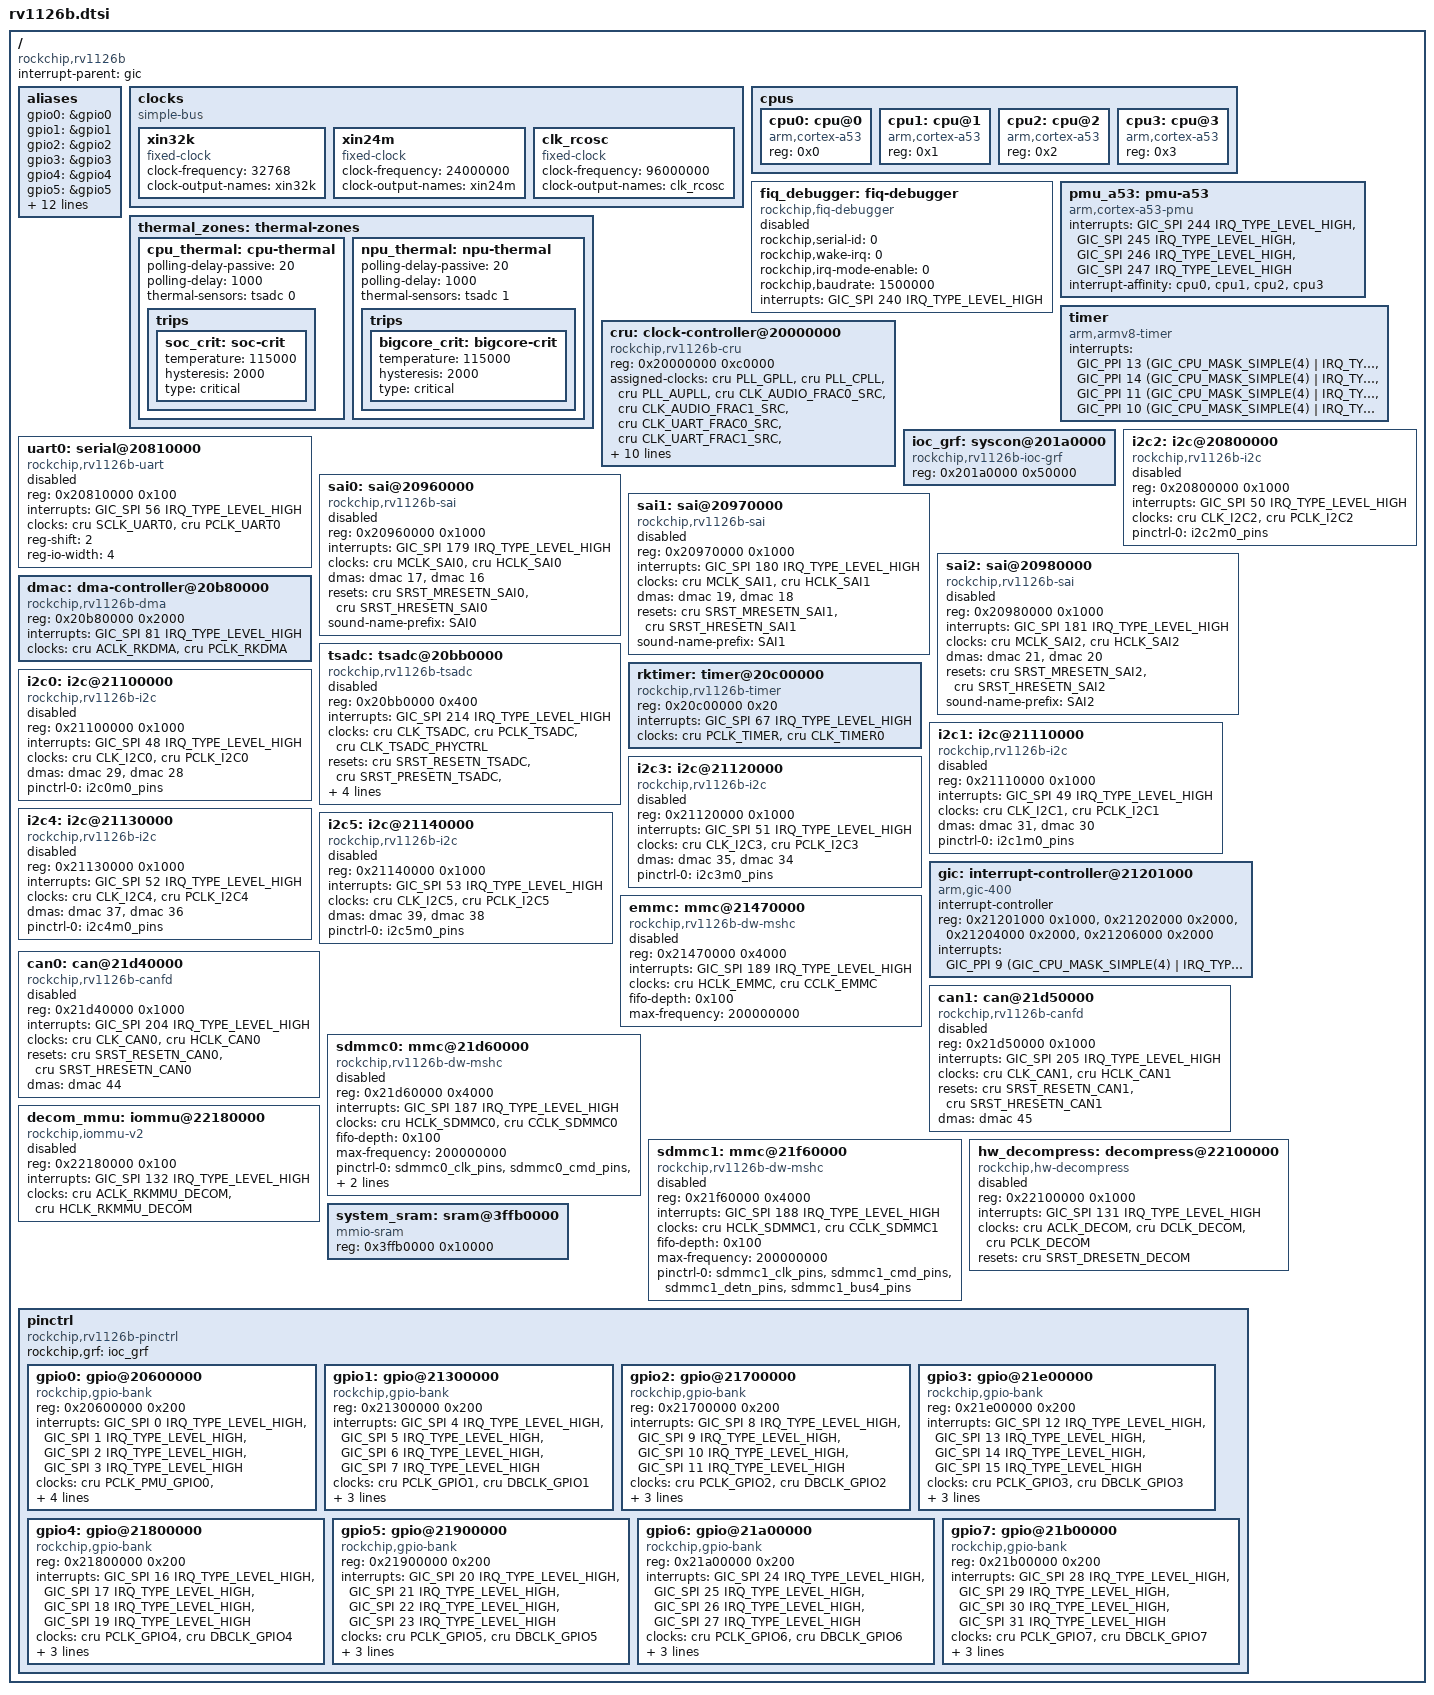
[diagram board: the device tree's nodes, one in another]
// SPDX-License-Identifier: (GPL-2.0+ OR MIT)
/*
 * Copyright (c) 2024 Rockchip Electronics Co., Ltd.
 */

#include <dt-bindings/clock/rockchip,rv1126b-cru.h>
#include <dt-bindings/interrupt-controller/arm-gic.h>
#include <dt-bindings/interrupt-controller/irq.h>
#include <dt-bindings/pinctrl/rockchip.h>
#include <dt-bindings/soc/rockchip,boot-mode.h>
#include <dt-bindings/soc/rockchip-system-status.h>

/ {
	compatible = "rockchip,rv1126b";

	interrupt-parent = <&gic>;
	#address-cells = <1>;
	#size-cells = <1>;

	aliases {
		gpio0 = &gpio0;
		gpio1 = &gpio1;
		gpio2 = &gpio2;
		gpio3 = &gpio3;
		gpio4 = &gpio4;
		gpio5 = &gpio5;
		gpio6 = &gpio6;
		gpio7 = &gpio7;
		i2c0 = &i2c0;
		i2c1 = &i2c1;
		i2c2 = &i2c2;
		i2c3 = &i2c3;
		i2c4 = &i2c4;
		i2c5 = &i2c5;
		mmc0 = &emmc;
		mmc1 = &sdmmc0;
		mmc2 = &sdmmc1;
		serial0 = &uart0;
	};

	clocks {
		compatible = "simple-bus";
		#address-cells = <1>;
		#size-cells = <1>;
		ranges;

		xin32k: xin32k {
			compatible = "fixed-clock";
			#clock-cells = <0>;
			clock-frequency = <32768>;
			clock-output-names = "xin32k";
		};

		xin24m: xin24m {
			compatible = "fixed-clock";
			#clock-cells = <0>;
			clock-frequency = <24000000>;
			clock-output-names = "xin24m";
		};

		clk_rcosc: clk_rcosc {
			compatible = "fixed-clock";
			#clock-cells = <0>;
			clock-frequency = <96000000>;
			clock-output-names = "clk_rcosc";
		};
	};

	cpus {
		#address-cells = <1>;
		#size-cells = <0>;

		cpu0: cpu@0 {
			device_type = "cpu";
			compatible = "arm,cortex-a53";
			reg = <0x0>;
		};
		cpu1: cpu@1 {
			device_type = "cpu";
			compatible = "arm,cortex-a53";
			reg = <0x1>;
		};
		cpu2: cpu@2 {
			device_type = "cpu";
			compatible = "arm,cortex-a53";
			reg = <0x2>;
		};
		cpu3: cpu@3 {
			device_type = "cpu";
			compatible = "arm,cortex-a53";
			reg = <0x3>;
		};
	};

	fiq_debugger: fiq-debugger {
		compatible = "rockchip,fiq-debugger";
		rockchip,serial-id = <0>;
		rockchip,wake-irq = <0>;
		rockchip,irq-mode-enable = <0>;
		rockchip,baudrate = <1500000>;  /* Only 115200 and 1500000 */
		interrupts = <GIC_SPI 240 IRQ_TYPE_LEVEL_HIGH>;
		status = "disabled";
	};

	pmu_a53: pmu-a53 {
		compatible = "arm,cortex-a53-pmu";
		interrupts = <GIC_SPI 244 IRQ_TYPE_LEVEL_HIGH>,
			     <GIC_SPI 245 IRQ_TYPE_LEVEL_HIGH>,
			     <GIC_SPI 246 IRQ_TYPE_LEVEL_HIGH>,
			     <GIC_SPI 247 IRQ_TYPE_LEVEL_HIGH>;
		interrupt-affinity = <&cpu0>, <&cpu1>, <&cpu2>, <&cpu3>;
	};

	thermal_zones: thermal-zones {
		cpu_thermal: cpu-thermal {
			polling-delay-passive = <20>; /* milliseconds */
			polling-delay = <1000>; /* milliseconds */
			thermal-sensors = <&tsadc 0>;
			trips {
				soc_crit: soc-crit {
					/* millicelsius */
					temperature = <115000>;
					/* millicelsius */
					hysteresis = <2000>;
					type = "critical";
				};
			};
		};
		npu_thermal: npu-thermal {
			polling-delay-passive = <20>; /* milliseconds */
			polling-delay = <1000>; /* milliseconds */
			thermal-sensors = <&tsadc 1>;
			trips {
				bigcore_crit: bigcore-crit {
					/* millicelsius */
					temperature = <115000>;
					/* millicelsius */
					hysteresis = <2000>;
					type = "critical";
				};
			};
		};
	};

	timer {
		compatible = "arm,armv8-timer";
		interrupts = <GIC_PPI 13 (GIC_CPU_MASK_SIMPLE(4) | IRQ_TYPE_LEVEL_LOW)>,
			     <GIC_PPI 14 (GIC_CPU_MASK_SIMPLE(4) | IRQ_TYPE_LEVEL_LOW)>,
			     <GIC_PPI 11 (GIC_CPU_MASK_SIMPLE(4) | IRQ_TYPE_LEVEL_LOW)>,
			     <GIC_PPI 10 (GIC_CPU_MASK_SIMPLE(4) | IRQ_TYPE_LEVEL_LOW)>;
	};

	cru: clock-controller@20000000 {
		compatible = "rockchip,rv1126b-cru";
		reg = <0x20000000 0xc0000>;
		#clock-cells = <1>;
		#reset-cells = <1>;

		assigned-clocks =
			<&cru PLL_GPLL>, <&cru PLL_CPLL>,
			<&cru PLL_AUPLL>, <&cru CLK_AUDIO_FRAC0_SRC>,
			<&cru CLK_AUDIO_FRAC1_SRC>, <&cru CLK_UART_FRAC0_SRC>,
			<&cru CLK_UART_FRAC1_SRC>, <&cru CLK_CM_FRAC0_SRC>,
			<&cru CLK_CM_FRAC1_SRC>, <&cru CLK_CM_FRAC2_SRC>,
			<&cru CLK_UART_FRAC0>, <&cru CLK_UART_FRAC1>,
			<&cru CLK_CM_FRAC0>, <&cru CLK_CM_FRAC1>,
			<&cru CLK_CM_FRAC2>, <&cru CLK_AUDIO_FRAC0>,
			<&cru CLK_AUDIO_FRAC1>;
		assigned-clock-rates =
			<1188000000>, <1000000000>,
			<786432000>, <786432000>,
			<786432000>, <1188000000>,
			<1188000000>, <1188000000>,
			<1188000000>, <786432000>,
			<96000000>, <128000000>,
			<18432000>, <500000000>,
			<250000000>, <45158400>,
			<49152000>;
	};

	ioc_grf: syscon@201a0000 {
		compatible = "rockchip,rv1126b-ioc-grf", "syscon";
		reg = <0x201a0000 0x50000>;
	};

	i2c2: i2c@20800000 {
		compatible = "rockchip,rv1126b-i2c", "rockchip,rk3399-i2c";
		reg = <0x20800000 0x1000>;
		interrupts = <GIC_SPI 50 IRQ_TYPE_LEVEL_HIGH>;
		#address-cells = <1>;
		#size-cells = <0>;
		clocks = <&cru CLK_I2C2>, <&cru PCLK_I2C2>;
		clock-names = "i2c", "pclk";
		pinctrl-names = "default";
		pinctrl-0 = <&i2c2m0_pins>;
		status = "disabled";
	};

	uart0: serial@20810000 {
		compatible = "rockchip,rv1126b-uart", "snps,dw-apb-uart";
		reg = <0x20810000 0x100>;
		interrupts = <GIC_SPI 56 IRQ_TYPE_LEVEL_HIGH>;
		clocks = <&cru SCLK_UART0>, <&cru PCLK_UART0>;
		clock-names = "baudclk", "apb_pclk";
		reg-shift = <2>;
		reg-io-width = <4>;
		status = "disabled";
	};

	sai0: sai@20960000 {
		compatible = "rockchip,rv1126b-sai", "rockchip,sai-v1";
		reg = <0x20960000 0x1000>;
		interrupts = <GIC_SPI 179 IRQ_TYPE_LEVEL_HIGH>;
		clocks = <&cru MCLK_SAI0>, <&cru HCLK_SAI0>;
		clock-names = "mclk", "hclk";
		dmas = <&dmac 17>, <&dmac 16>;
		dma-names = "tx", "rx";
		resets = <&cru SRST_MRESETN_SAI0>, <&cru SRST_HRESETN_SAI0>;
		reset-names = "m", "h";
		#sound-dai-cells = <0>;
		sound-name-prefix = "SAI0";
		status = "disabled";
	};

	sai1: sai@20970000 {
		compatible = "rockchip,rv1126b-sai", "rockchip,sai-v1";
		reg = <0x20970000 0x1000>;
		interrupts = <GIC_SPI 180 IRQ_TYPE_LEVEL_HIGH>;
		clocks = <&cru MCLK_SAI1>, <&cru HCLK_SAI1>;
		clock-names = "mclk", "hclk";
		dmas = <&dmac 19>, <&dmac 18>;
		dma-names = "tx", "rx";
		resets = <&cru SRST_MRESETN_SAI1>, <&cru SRST_HRESETN_SAI1>;
		reset-names = "m", "h";
		#sound-dai-cells = <0>;
		sound-name-prefix = "SAI1";
		status = "disabled";
	};

	sai2: sai@20980000 {
		compatible = "rockchip,rv1126b-sai", "rockchip,sai-v1";
		reg = <0x20980000 0x1000>;
		interrupts = <GIC_SPI 181 IRQ_TYPE_LEVEL_HIGH>;
		clocks = <&cru MCLK_SAI2>, <&cru HCLK_SAI2>;
		clock-names = "mclk", "hclk";
		dmas = <&dmac 21>, <&dmac 20>;
		dma-names = "tx", "rx";
		resets = <&cru SRST_MRESETN_SAI2>, <&cru SRST_HRESETN_SAI2>;
		reset-names = "m", "h";
		#sound-dai-cells = <0>;
		sound-name-prefix = "SAI2";
		status = "disabled";
	};

	dmac: dma-controller@20b80000 {
		compatible = "rockchip,rv1126b-dma", "rockchip,dma";
		reg = <0x20b80000 0x2000>;
		interrupts = <GIC_SPI 81 IRQ_TYPE_LEVEL_HIGH>;
		clocks = <&cru ACLK_RKDMA>, <&cru PCLK_RKDMA>;
		clock-names = "aclk", "pclk";
		#dma-cells = <1>;
	};

	tsadc: tsadc@20bb0000 {
		compatible = "rockchip,rv1126b-tsadc";
		reg = <0x20bb0000 0x400>;
		interrupts = <GIC_SPI 214 IRQ_TYPE_LEVEL_HIGH>;
		clocks = <&cru CLK_TSADC>, <&cru PCLK_TSADC>,
			 <&cru CLK_TSADC_PHYCTRL>;
		clock-names = "tsadc", "apb_pclk", "tsadc_phyctrl";
		resets = <&cru SRST_RESETN_TSADC>, <&cru SRST_PRESETN_TSADC>,
			 <&cru SRST_RESETN_TSADC_PHYCTRL>;
		reset-names = "tsadc", "tsadc-apb", "tsadc-phy";
		#thermal-sensor-cells = <1>;
		rockchip,hw-tshut-temp = <120000>;
		rockchip,hw-tshut-mode = <0>; /* tshut mode 0:CRU 1:GPIO */
		rockchip,hw-tshut-polarity = <0>; /* tshut polarity 0:LOW 1:HIGH */
		status = "disabled";
	};

	rktimer: timer@20c00000 {
		compatible = "rockchip,rv1126b-timer", "rockchip,rk3288-timer";
		reg = <0x20c00000 0x20>;
		interrupts = <GIC_SPI 67 IRQ_TYPE_LEVEL_HIGH>;
		clocks = <&cru PCLK_TIMER>, <&cru CLK_TIMER0>;
		clock-names = "pclk", "timer";
	};

	i2c0: i2c@21100000 {
		compatible = "rockchip,rv1126b-i2c", "rockchip,rk3399-i2c";
		reg = <0x21100000 0x1000>;
		interrupts = <GIC_SPI 48 IRQ_TYPE_LEVEL_HIGH>;
		#address-cells = <1>;
		#size-cells = <0>;
		clocks = <&cru CLK_I2C0>, <&cru PCLK_I2C0>;
		clock-names = "i2c", "pclk";
		dmas = <&dmac 29>, <&dmac 28>;
		dma-names = "tx", "rx";
		pinctrl-names = "default";
		pinctrl-0 = <&i2c0m0_pins>;
		status = "disabled";
	};

	i2c1: i2c@21110000 {
		compatible = "rockchip,rv1126b-i2c", "rockchip,rk3399-i2c";
		reg = <0x21110000 0x1000>;
		interrupts = <GIC_SPI 49 IRQ_TYPE_LEVEL_HIGH>;
		#address-cells = <1>;
		#size-cells = <0>;
		clocks = <&cru CLK_I2C1>, <&cru PCLK_I2C1>;
		clock-names = "i2c", "pclk";
		dmas = <&dmac 31>, <&dmac 30>;
		dma-names = "tx", "rx";
		pinctrl-names = "default";
		pinctrl-0 = <&i2c1m0_pins>;
		status = "disabled";
	};

	i2c3: i2c@21120000 {
		compatible = "rockchip,rv1126b-i2c", "rockchip,rk3399-i2c";
		reg = <0x21120000 0x1000>;
		interrupts = <GIC_SPI 51 IRQ_TYPE_LEVEL_HIGH>;
		#address-cells = <1>;
		#size-cells = <0>;
		clocks = <&cru CLK_I2C3>, <&cru PCLK_I2C3>;
		clock-names = "i2c", "pclk";
		dmas = <&dmac 35>, <&dmac 34>;
		dma-names = "tx", "rx";
		pinctrl-names = "default";
		pinctrl-0 = <&i2c3m0_pins>;
		status = "disabled";
	};

	i2c4: i2c@21130000 {
		compatible = "rockchip,rv1126b-i2c", "rockchip,rk3399-i2c";
		reg = <0x21130000 0x1000>;
		interrupts = <GIC_SPI 52 IRQ_TYPE_LEVEL_HIGH>;
		#address-cells = <1>;
		#size-cells = <0>;
		clocks = <&cru CLK_I2C4>, <&cru PCLK_I2C4>;
		clock-names = "i2c", "pclk";
		dmas = <&dmac 37>, <&dmac 36>;
		dma-names = "tx", "rx";
		pinctrl-names = "default";
		pinctrl-0 = <&i2c4m0_pins>;
		status = "disabled";
	};

	i2c5: i2c@21140000 {
		compatible = "rockchip,rv1126b-i2c", "rockchip,rk3399-i2c";
		reg = <0x21140000 0x1000>;
		interrupts = <GIC_SPI 53 IRQ_TYPE_LEVEL_HIGH>;
		#address-cells = <1>;
		#size-cells = <0>;
		clocks = <&cru CLK_I2C5>, <&cru PCLK_I2C5>;
		clock-names = "i2c", "pclk";
		dmas = <&dmac 39>, <&dmac 38>;
		dma-names = "tx", "rx";
		pinctrl-names = "default";
		pinctrl-0 = <&i2c5m0_pins>;
		status = "disabled";
	};

	gic: interrupt-controller@21201000 {
		compatible = "arm,gic-400";
		#interrupt-cells = <3>;
		#address-cells = <0>;
		interrupt-controller;
		reg = <0x21201000 0x1000>,
		      <0x21202000 0x2000>,
		      <0x21204000 0x2000>,
		      <0x21206000 0x2000>;
		interrupts = <GIC_PPI 9 (GIC_CPU_MASK_SIMPLE(4) | IRQ_TYPE_LEVEL_LOW)>;
	};

	emmc: mmc@21470000 {
		compatible = "rockchip,rv1126b-dw-mshc", "rockchip,rk3288-dw-mshc";
		reg = <0x21470000 0x4000>;
		interrupts = <GIC_SPI 189 IRQ_TYPE_LEVEL_HIGH>;
		clocks = <&cru HCLK_EMMC>, <&cru CCLK_EMMC>;
		clock-names = "biu", "ciu";
		fifo-depth = <0x100>;
		max-frequency = <200000000>;
		status = "disabled";
	};

	can0: can@21d40000 {
		compatible = "rockchip,rv1126b-canfd";
		reg = <0x21d40000 0x1000>;
		interrupts = <GIC_SPI 204 IRQ_TYPE_LEVEL_HIGH>;
		clocks = <&cru CLK_CAN0>, <&cru HCLK_CAN0>;
		clock-names = "baudclk", "apb_pclk";
		resets = <&cru SRST_RESETN_CAN0>, <&cru SRST_HRESETN_CAN0>;
		reset-names = "can", "can-apb";
		dmas = <&dmac 44>;
		dma-names = "rx";
		status = "disabled";
	};

	can1: can@21d50000 {
		compatible = "rockchip,rv1126b-canfd";
		reg = <0x21d50000 0x1000>;
		interrupts = <GIC_SPI 205 IRQ_TYPE_LEVEL_HIGH>;
		clocks = <&cru CLK_CAN1>, <&cru HCLK_CAN1>;
		clock-names = "baudclk", "apb_pclk";
		resets = <&cru SRST_RESETN_CAN1>, <&cru SRST_HRESETN_CAN1>;
		reset-names = "can", "can-apb";
		dmas = <&dmac 45>;
		dma-names = "rx";
		status = "disabled";
	};

	sdmmc0: mmc@21d60000 {
		compatible = "rockchip,rv1126b-dw-mshc", "rockchip,rk3288-dw-mshc";
		reg = <0x21d60000 0x4000>;
		interrupts = <GIC_SPI 187 IRQ_TYPE_LEVEL_HIGH>;
		clocks = <&cru HCLK_SDMMC0>, <&cru CCLK_SDMMC0>;
		clock-names = "biu", "ciu";
		fifo-depth = <0x100>;
		max-frequency = <200000000>;
		pinctrl-names = "normal", "idle";
		pinctrl-0 = <&sdmmc0_clk_pins &sdmmc0_cmd_pins &sdmmc0_detn_pins &sdmmc0_bus4_pins>;
		pinctrl-1 = <&sdmmc0_idle_pins &sdmmc0_detn_pins>;
		status = "disabled";
	};

	sdmmc1: mmc@21f60000 {
		compatible = "rockchip,rv1126b-dw-mshc", "rockchip,rk3288-dw-mshc";
		reg = <0x21f60000 0x4000>;
		interrupts = <GIC_SPI 188 IRQ_TYPE_LEVEL_HIGH>;
		clocks = <&cru HCLK_SDMMC1>, <&cru CCLK_SDMMC1>;
		clock-names = "biu", "ciu";
		fifo-depth = <0x100>;
		max-frequency = <200000000>;
		pinctrl-names = "default";
		pinctrl-0 = <&sdmmc1_clk_pins &sdmmc1_cmd_pins &sdmmc1_detn_pins &sdmmc1_bus4_pins>;
		status = "disabled";
	};

	hw_decompress: decompress@22100000 {
		compatible = "rockchip,hw-decompress";
		reg = <0x22100000 0x1000>;
		interrupts = <GIC_SPI 131 IRQ_TYPE_LEVEL_HIGH>;
		clocks = <&cru ACLK_DECOM>, <&cru DCLK_DECOM>, <&cru PCLK_DECOM>;
		clock-names = "aclk", "dclk", "pclk";
		resets = <&cru SRST_DRESETN_DECOM>;
		reset-names = "dresetn";
		status = "disabled";
	};

	decom_mmu: iommu@22180000 {
		compatible = "rockchip,iommu-v2";
		reg = <0x22180000 0x100>;
		interrupts = <GIC_SPI 132 IRQ_TYPE_LEVEL_HIGH>;
		interrupt-names = "decom_mmu";
		clocks = <&cru ACLK_RKMMU_DECOM>, <&cru HCLK_RKMMU_DECOM>;
		clock-names = "aclk", "iface";
		#iommu-cells = <0>;
		status = "disabled";
	};

	system_sram: sram@3ffb0000 {
		compatible = "mmio-sram";
		reg = <0x3ffb0000 0x10000>;
		#address-cells = <1>;
		#size-cells = <1>;
		ranges = <0 0x3ffb0000 0x10000>;
	};

	pinctrl: pinctrl {
		compatible = "rockchip,rv1126b-pinctrl";
		rockchip,grf = <&ioc_grf>;
		#address-cells = <1>;
		#size-cells = <1>;
		ranges;

		gpio0: gpio@20600000 {
			compatible = "rockchip,gpio-bank";
			reg = <0x20600000 0x200>;
			interrupts = <GIC_SPI 0 IRQ_TYPE_LEVEL_HIGH>,
				     <GIC_SPI 1 IRQ_TYPE_LEVEL_HIGH>,
				     <GIC_SPI 2 IRQ_TYPE_LEVEL_HIGH>,
				     <GIC_SPI 3 IRQ_TYPE_LEVEL_HIGH>;
			clocks = <&cru PCLK_PMU_GPIO0>, <&cru DBCLK_PMU_GPIO0>;

			gpio-controller;
			#gpio-cells = <2>;
			gpio-ranges = <&pinctrl 0 0 32>;
			interrupt-controller;
			#interrupt-cells = <2>;
		};

		gpio1: gpio@21300000 {
			compatible = "rockchip,gpio-bank";
			reg = <0x21300000 0x200>;
			interrupts = <GIC_SPI 4 IRQ_TYPE_LEVEL_HIGH>,
				     <GIC_SPI 5 IRQ_TYPE_LEVEL_HIGH>,
				     <GIC_SPI 6 IRQ_TYPE_LEVEL_HIGH>,
				     <GIC_SPI 7 IRQ_TYPE_LEVEL_HIGH>;
			clocks = <&cru PCLK_GPIO1>, <&cru DBCLK_GPIO1>;

			gpio-controller;
			#gpio-cells = <2>;
			gpio-ranges = <&pinctrl 0 32 32>;
			interrupt-controller;
			#interrupt-cells = <2>;
		};

		gpio2: gpio@21700000 {
			compatible = "rockchip,gpio-bank";
			reg = <0x21700000 0x200>;
			interrupts = <GIC_SPI 8 IRQ_TYPE_LEVEL_HIGH>,
				     <GIC_SPI 9 IRQ_TYPE_LEVEL_HIGH>,
				     <GIC_SPI 10 IRQ_TYPE_LEVEL_HIGH>,
				     <GIC_SPI 11 IRQ_TYPE_LEVEL_HIGH>;
			clocks = <&cru PCLK_GPIO2>, <&cru DBCLK_GPIO2>;

			gpio-controller;
			#gpio-cells = <2>;
			gpio-ranges = <&pinctrl 0 64 32>;
			interrupt-controller;
			#interrupt-cells = <2>;
		};

		gpio3: gpio@21e00000 {
			compatible = "rockchip,gpio-bank";
			reg = <0x21e00000 0x200>;
			interrupts = <GIC_SPI 12 IRQ_TYPE_LEVEL_HIGH>,
				     <GIC_SPI 13 IRQ_TYPE_LEVEL_HIGH>,
				     <GIC_SPI 14 IRQ_TYPE_LEVEL_HIGH>,
				     <GIC_SPI 15 IRQ_TYPE_LEVEL_HIGH>;
			clocks = <&cru PCLK_GPIO3>, <&cru DBCLK_GPIO3>;

			gpio-controller;
			#gpio-cells = <2>;
			gpio-ranges = <&pinctrl 0 96 32>;
			interrupt-controller;
			#interrupt-cells = <2>;
		};

		gpio4: gpio@21800000 {
			compatible = "rockchip,gpio-bank";
			reg = <0x21800000 0x200>;
			interrupts = <GIC_SPI 16 IRQ_TYPE_LEVEL_HIGH>,
				     <GIC_SPI 17 IRQ_TYPE_LEVEL_HIGH>,
				     <GIC_SPI 18 IRQ_TYPE_LEVEL_HIGH>,
				     <GIC_SPI 19 IRQ_TYPE_LEVEL_HIGH>;
			clocks = <&cru PCLK_GPIO4>, <&cru DBCLK_GPIO4>;

			gpio-controller;
			#gpio-cells = <2>;
			gpio-ranges = <&pinctrl 0 128 32>;
			interrupt-controller;
			#interrupt-cells = <2>;
		};

		gpio5: gpio@21900000 {
			compatible = "rockchip,gpio-bank";
			reg = <0x21900000 0x200>;
			interrupts = <GIC_SPI 20 IRQ_TYPE_LEVEL_HIGH>,
				     <GIC_SPI 21 IRQ_TYPE_LEVEL_HIGH>,
				     <GIC_SPI 22 IRQ_TYPE_LEVEL_HIGH>,
				     <GIC_SPI 23 IRQ_TYPE_LEVEL_HIGH>;
			clocks = <&cru PCLK_GPIO5>, <&cru DBCLK_GPIO5>;

			gpio-controller;
			#gpio-cells = <2>;
			gpio-ranges = <&pinctrl 0 160 32>;
			interrupt-controller;
			#interrupt-cells = <2>;
		};

		gpio6: gpio@21a00000 {
			compatible = "rockchip,gpio-bank";
			reg = <0x21a00000 0x200>;
			interrupts = <GIC_SPI 24 IRQ_TYPE_LEVEL_HIGH>,
				     <GIC_SPI 25 IRQ_TYPE_LEVEL_HIGH>,
				     <GIC_SPI 26 IRQ_TYPE_LEVEL_HIGH>,
				     <GIC_SPI 27 IRQ_TYPE_LEVEL_HIGH>;
			clocks = <&cru PCLK_GPIO6>, <&cru DBCLK_GPIO6>;

			gpio-controller;
			#gpio-cells = <2>;
			gpio-ranges = <&pinctrl 0 192 32>;
			interrupt-controller;
			#interrupt-cells = <2>;
		};

		gpio7: gpio@21b00000 {
			compatible = "rockchip,gpio-bank";
			reg = <0x21b00000 0x200>;
			interrupts = <GIC_SPI 28 IRQ_TYPE_LEVEL_HIGH>,
				     <GIC_SPI 29 IRQ_TYPE_LEVEL_HIGH>,
				     <GIC_SPI 30 IRQ_TYPE_LEVEL_HIGH>,
				     <GIC_SPI 31 IRQ_TYPE_LEVEL_HIGH>;
			clocks = <&cru PCLK_GPIO7>, <&cru DBCLK_GPIO7>;

			gpio-controller;
			#gpio-cells = <2>;
			gpio-ranges = <&pinctrl 0 224 32>;
			interrupt-controller;
			#interrupt-cells = <2>;
		};
	};
};

#include "rv1126b-pinctrl.dtsi"
